# STM32H7x5 register map
File version: 1.1
CPU: CM7 r0p0, little endian, no MPU, no FPU, 3 interrupt priority bits
Registers are 32-bit, read-write, reset 0x0 unless marked. A register's access mark holds for its fields unless they carry their own. Offsets are from the block's base; [hi:lo] are bit positions; {n}, {i} and the like mark numbered series; 'fields as' and 'values as' point back to an identical list; <NAME> marks a mode.

## MDMA
Base 0x52000000
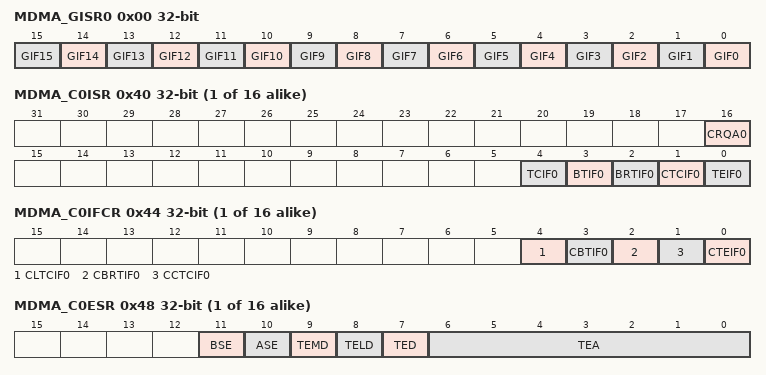
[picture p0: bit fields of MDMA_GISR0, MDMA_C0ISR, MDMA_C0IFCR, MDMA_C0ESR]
0x00 MDMA_GISR0 ro — MDMA Global Interrupt/Status Register
  [n] GIF{n} (n=0..15) — Channel x global interrupt flag (x=...) This bit is set and reset by hardware. It is a logical OR of all the Channel x interrupt flags (CTCIFx, BTIFx, BRTIFx, TEIFx) which are enabled in the interrupt mask register (CTCIEx, BTIEx, BRTIEx, TEIEx)
{0x40+0x40*i} MDMA_C{i}ISR ro (i=0..15) — MDMA channel x interrupt/status register
  [16] CRQA{i} — channel x request active flag
  [4] TCIF{i} — channel x buffer transfer complete
  [3] BTIF{i} — Channel x block transfer complete interrupt flag This bit is set by hardware. It is cleared by software writing 1 to the corresponding bit in the DMA_IFCRy register.
  [2] BRTIF{i} — Channel x block repeat transfer complete interrupt flag This bit is set by hardware. It is cleared by software writing 1 to the corresponding bit in the DMA_IFCRy register.
  [1] CTCIF{i} — Channel x Channel Transfer Complete interrupt flag This bit is set by hardware. It is cleared by software writing 1 to the corresponding bit in the DMA_IFCRy register. CTC is set when the last block was transferred and the channel has been automatically disabled. CTC is also set when the channel is suspended, as a result of writing EN bit to 0.
  [0] TEIF{i} — Channel x transfer error interrupt flag This bit is set by hardware. It is cleared by software writing 1 to the corresponding bit in the DMA_IFCRy register.
{0x44+0x40*i} MDMA_C{i}IFCR wo (i=0..15) — MDMA channel x interrupt flag clear register
  [4] CLTCIF{i} — CLear buffer Transfer Complete Interrupt Flag for channel x Writing a 1 into this bit clears TCIFx in the MDMA_ISRy register
  [3] CBTIF{i} — Channel x Clear block transfer complete interrupt flag Writing a 1 into this bit clears BTIFx in the MDMA_ISRy register
  [2] CBRTIF{i} — Channel x clear block repeat transfer complete interrupt flag Writing a 1 into this bit clears BRTIFx in the MDMA_ISRy register
  [1] CCTCIF{i} — Clear Channel transfer complete interrupt flag for channel x Writing a 1 into this bit clears CTCIFx in the MDMA_ISRy register
  [0] CTEIF{i} — Channel x clear transfer error interrupt flag Writing a 1 into this bit clears TEIFx in the MDMA_ISRy register
{0x48+0x40*i} MDMA_C{i}ESR ro (i=0..15) — MDMA Channel x error status register
  [11] BSE — Block Size Error These bit is set by HW, when the block size is not an integer multiple of the data size either for source or destination. TED will indicate whether the problem is on the source or destination. It is cleared by software writing 1 to the CTEIFx bit in the DMA_IFCRy register.
  [10] ASE — Address/Size Error These bit is set by HW, when the programmed address is not aligned with the data size. TED will indicate whether the problem is on the source or destination. It is cleared by software writing 1 to the CTEIFx bit in the DMA_IFCRy register.
  [9] TEMD — Transfer Error Mask Data These bit is set by HW, in case of a transfer error while writing the Mask Data. It is cleared by software writing 1 to the CTEIFx bit in the DMA_IFCRy register.
  [8] TELD — Transfer Error Link Data These bit is set by HW, in case of a transfer error while reading the block link data structure. It is cleared by software writing 1 to the CTEIFx bit in the DMA_IFCRy register.
  [7] TED — Transfer Error Direction These bit is set and cleared by HW, in case of an MDMA data transfer error.
  [6:0] TEA — Transfer Error Address These bits are set and cleared by HW, in case of an MDMA data transfer error. It is used in conjunction with TED. This field indicates the 7 LSBits of the address which generated a transfer/access error. It may be used by SW to retrieve the failing address, by adding this value (truncated to the buffer transfer length size) to the current SAR/DAR value. Note: The SAR/DAR current value doesnt reflect this last address due to the FIFO management system. The SAR/DAR are only updated at the end of a (buffer) transfer (of TLEN+1 bytes). Note: It is not set in case of a link data error.
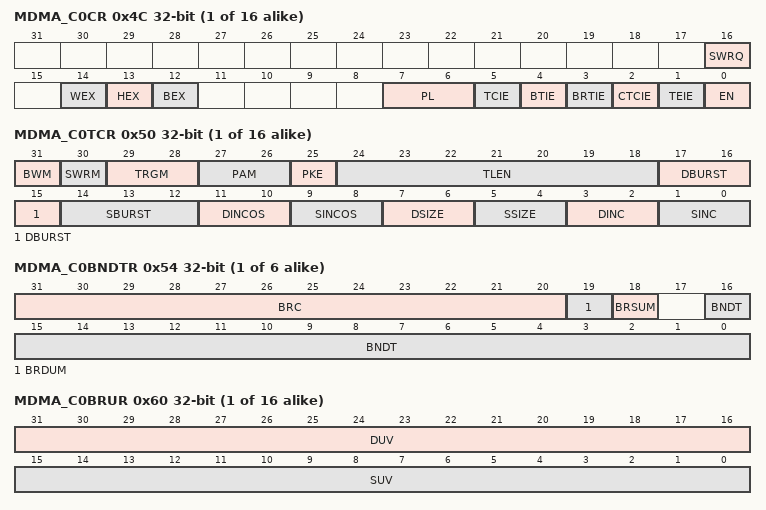
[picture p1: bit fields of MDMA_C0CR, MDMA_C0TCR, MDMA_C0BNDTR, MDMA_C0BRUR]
{0x4C+0x40*i} MDMA_C{i}CR access per field (i=0..15) — This register is used to control the concerned channel.
  [16] SWRQ wo — SW ReQuest Writing a 1 into this bit sets the CRQAx in MDMA_ISRy register, activating the request on Channel x Note: Either the whole CxCR register or the 8-bit/16-bit register @ Address offset: 0x4E + 0x40 chn may be used for SWRQ activation. In case of a SW request, acknowledge is not generated (neither HW signal, nor CxMAR write access).
  [14] WEX rw — Word Endianness exchange
  [13] HEX rw — Half word Endianes exchange
  [12] BEX rw — byte Endianness exchange
  [7:6] PL rw — Priority level These bits are set and cleared by software. These bits are protected and can be written only if EN is 0.
  [5] TCIE rw — buffer Transfer Complete interrupt enable This bit is set and cleared by software.
  [4] BTIE rw — Block Transfer interrupt enable This bit is set and cleared by software.
  [3] BRTIE rw — Block Repeat transfer interrupt enable This bit is set and cleared by software.
  [2] CTCIE rw — Channel Transfer Complete interrupt enable This bit is set and cleared by software.
  [1] TEIE rw — Transfer error interrupt enable This bit is set and cleared by software.
  [0] EN rw — channel enable
{0x50+0x40*i} MDMA_C{i}TCR (i=0..15) — This register is used to configure the concerned channel.
  [31] BWM — Bufferable Write Mode This bit is set and cleared by software. This bit is protected and can be written only if EN is 0. Note: All MDMA destination accesses are non-cacheable.
  [30] SWRM — SW Request Mode This bit is set and cleared by software. If a HW or SW request is currently active, the bit change will be delayed until the current transfer is completed. If the CxMAR contains a valid address, the CxMDR value will also be written @ CxMAR address. This bit is protected and can be written only if EN is 0.
  [29:28] TRGM — Trigger Mode These bits are set and cleared by software. Note: If TRGM is 11 for the current block, all the values loaded at the end of the current block through the linked list mechanism must keep the same value (TRGM=11) and the same SWRM value, otherwise the result is undefined. These bits are protected and can be written only if EN is 0.
  [27:26] PAM — Padding/Alignement Mode These bits are set and cleared by software. Case 1: Source data size smaller than destination data size - 3 options are valid. Case 2: Source data size larger than destination data size. The remainder part is discarded. When PKE = 1 or DSIZE=SSIZE, these bits are ignored. These bits are protected and can be written only if EN is 0
  [25] PKE — PacK Enable These bit is set and cleared by software. If the Source Size is smaller than the destination, it will be padded according to the PAM value. If the Source data size is larger than the destination one, it will be truncated. The alignment will be done according to the PAM[0] value. This bit is protected and can be written only if EN is 0
  [24:18] TLEN — buffer transfer lengh
  [17:15] DBURST — Destination burst transfer configuration
  [14:12] SBURST — source burst transfer configuration
  [11:10] DINCOS — Destination increment offset
  [9:8] SINCOS — source increment offset size
  [7:6] DSIZE — Destination data size These bits are set and cleared by software. These bits are protected and can be written only if EN is 0. Note: If a value of 11 is programmed for the TCM access/AHB port, a transfer error will occur (TEIF bit set) If DINCOS < DSIZE and DINC ≠ 00, the result will be unpredictable. Note: DSIZE = 11 (double-word) is forbidden when destination is TCM/AHB bus (DBUS=1).
  [5:4] SSIZE — Source data size These bits are set and cleared by software. These bits are protected and can be written only if EN is 0 Note: If a value of 11 is programmed for the TCM access/AHB port, a transfer error will occur (TEIF bit set) If SINCOS < SSIZE and SINC ≠ 00, the result will be unpredictable. Note: SSIZE = 11 (double-word) is forbidden when source is TCM/AHB bus (SBUS=1).
  [3:2] DINC — Destination increment mode These bits are set and cleared by software. These bits are protected and can be written only if EN is 0 Note: When destination is AHB (DBUS=1), DINC = 00 is forbidden.
  [1:0] SINC — Source increment mode These bits are set and cleared by software. These bits are protected and can be written only if EN is 0 Note: When source is AHB (SBUS=1), SINC = 00 is forbidden. In Linked List Mode, at the end of a block (single or last block in repeated block transfer mode), this register will be loaded from memory (from address given by current LAR[31:0] + 0x00).
{0x54+0x40*i} MDMA_C{i}BNDTR (i=0..5) — MDMA Channel x block number of data register
  [31:20] BRC — Block Repeat Count This field contains the number of repetitions of the current block (0 to 4095). When the channel is enabled, this register is read-only, indicating the remaining number of blocks, excluding the current one. This register decrements after each complete block transfer. Once the last block transfer has completed, this register can either stay at zero or be reloaded automatically from memory (in Linked List mode - i.e. Link Address valid). These bits are protected and can be written only if EN is 0.
  [19] BRDUM — Block Repeat Destination address Update Mode These bits are protected and can be written only if EN is 0.
  [18] BRSUM — Block Repeat Source address Update Mode These bits are protected and can be written only if EN is 0.
  [16:0] BNDT — block number of data to transfer
{0x58+0x40*i} MDMA_C{i}SAR (i=0..15) — MDMA channel x source address register
  [31:0] SAR — source adr base
{0x5C+0x40*i} MDMA_C{i}DAR (i=0..15) — MDMA channel x destination address register
  [31:0] DAR — Destination adr base
{0x60+0x40*i} MDMA_C{i}BRUR (i=0..15) — MDMA channel x Block Repeat address Update register
  [31:16] DUV — destination address update
  [15:0] SUV — source adresse update value
{0x64+0x40*i} MDMA_C{i}LAR (i=0..15) — MDMA channel x Link Address register
  [31:0] LAR — Link address register
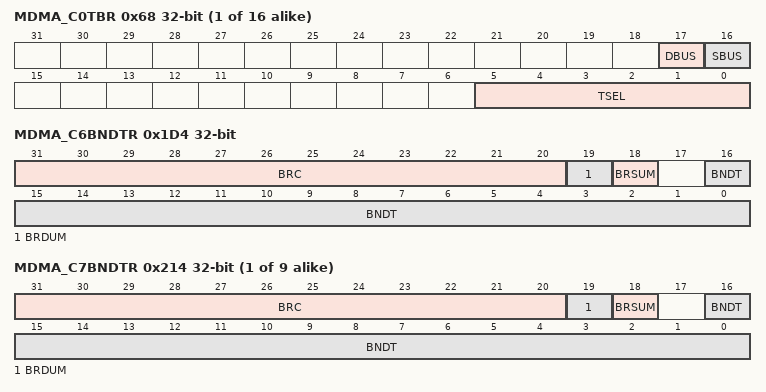
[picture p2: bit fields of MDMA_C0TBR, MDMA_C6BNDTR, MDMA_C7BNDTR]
{0x68+0x40*i} MDMA_C{i}TBR (i=0..15) — MDMA channel x Trigger and Bus selection Register
  [17] DBUS — Destination BUS slect This bit is protected and can be written only if EN is 0.
  [16] SBUS — Source BUS select This bit is protected and can be written only if EN is 0.
  [5:0] TSEL — Trigger selection
{0x70+0x40*i} MDMA_C{i}MAR (i=0..15) — MDMA channel x Mask address register
  [31:0] MAR — Mask address
{0x74+0x40*i} MDMA_C{i}MDR (i=0..15) — MDMA channel x Mask Data register
  [31:0] MDR — Mask data
0x1D4 MDMA_C6BNDTR — MDMA Channel x block number of data register
  [31:20] BRC — Block Repeat Count This field contains the number of repetitions of the current block (0 to 4095). When the channel is enabled, this register is read-only, indicating the remaining number of blocks, excluding the current one. This register decrements after each complete block transfer. Once the last block transfer has completed, this register can either stay at zero or be reloaded automatically from memory (in Linked List mode - i.e. Link Address valid). These bits are protected and can be written only if EN is 0
  [19] BRDUM — Block Repeat Destination address Update Mode These bits are protected and can be written only if EN is 0.
  [18] BRSUM — Block Repeat Source address Update Mode These bits are protected and can be written only if EN is 0.
  [16:0] BNDT — block number of data to transfer
{0x54+0x40*i} MDMA_C{i}BNDTR (i=7..15) — MDMA Channel x block number of data register
  fields as MDMA_C0BNDTR
